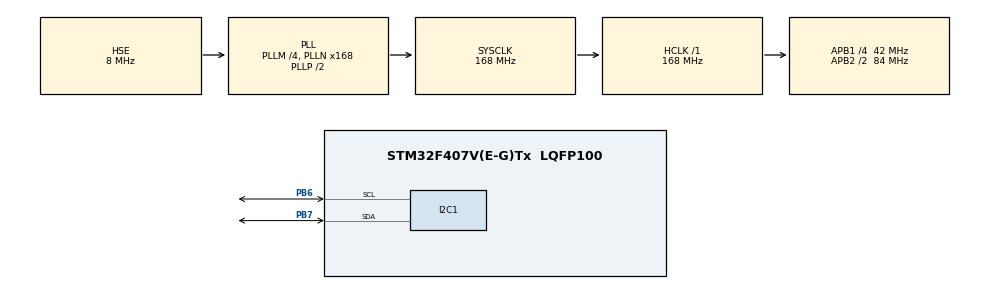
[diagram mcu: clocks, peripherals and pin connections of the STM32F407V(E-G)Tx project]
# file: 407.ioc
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Mcu.Family=STM32F4
Mcu.Name=STM32F407V(E-G)Tx
Mcu.Package=LQFP100
NVIC.PriorityGroup=NVIC_PRIORITYGROUP_4
PA13.Mode=Serial_Wire
PA13.Signal=SYS_JTMS-SWDIO
PA14.Mode=Serial_Wire
PA14.Signal=SYS_JTCK-SWCLK
PB6.Mode=I2C
PB6.Signal=I2C1_SCL
PB7.Mode=I2C
PB7.Signal=I2C1_SDA
PH0-OSC_IN.Mode=HSE-External-Oscillator
PH0-OSC_IN.Signal=RCC_OSC_IN
PH1-OSC_OUT.Mode=HSE-External-Oscillator
PH1-OSC_OUT.Signal=RCC_OSC_OUT
ProjectManager.HeapSize=0x200
ProjectManager.StackSize=0x400
ProjectManager.TargetToolchain=MDK-ARM V5.27
RCC.48MHZClocksFreq_Value=84000000
RCC.AHBFreq_Value=168000000
RCC.APB1CLKDivider=RCC_HCLK_DIV4
RCC.APB1Freq_Value=42000000
RCC.APB1TimFreq_Value=84000000
RCC.APB2CLKDivider=RCC_HCLK_DIV2
RCC.APB2Freq_Value=84000000
RCC.APB2TimFreq_Value=168000000
RCC.CortexFreq_Value=168000000
RCC.HCLKFreq_Value=168000000
RCC.HSE_VALUE=8000000
RCC.HSI_VALUE=16000000
RCC.LSE_VALUE=32768
RCC.PLLM=4
RCC.PLLN=168
RCC.PLLSourceVirtual=RCC_PLLSOURCE_HSE
RCC.SYSCLKFreq_VALUE=168000000
RCC.SYSCLKSource=RCC_SYSCLKSOURCE_PLLCLK
RCC.VCOOutputFreq_Value=336000000
board=custom

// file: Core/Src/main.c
/* USER CODE BEGIN Header */
/***************************************************************************//**
  文件: main.c
  作者: Zhengyu https://gzwelink.taobao.com
  版本: V1.0.0
  时间: 20220401
	平台:MINI-F407VET6

*******************************************************************************/
/* USER CODE END Header */
#include "main.h"
#include "i2c.h"
#include "gpio.h"
#include "oled.h"
/* USER CODE BEGIN Includes */
uint8_t DataBuff[2];//存储数组
float LightData;//光照强度（含小数位，单位lx）
uint32_t LightData_Hex;//光照强度（整数，单位lx）
/* USER CODE END Includes */

/* USER CODE BEGIN PTD */
//写入1字节数据到BH170,设备地址0x46
void BH170_WriteReg(uint8_t reg_add,uint8_t reg_dat)
{
	HAL_I2C_Mem_Write(&hi2c1,0x46,reg_add,1,&reg_dat,1,1000);
}

//读取BH170数据,设备地址0x46
void BH170_ReadData(uint8_t reg_add,unsigned char*Read,uint8_t num)
{
 HAL_I2C_Mem_Read(&hi2c1,0x46,reg_add,1,Read,num,1000);
}
/* USER CODE END PTD */

void SystemClock_Config(void);

int main(void)
{

  /* MCU Configuration--------------------------------------------------------*/

  /* Reset of all peripherals, Initializes the Flash interface and the Systick. */
  HAL_Init();

  /* Configure the system clock */
  SystemClock_Config();

  /* Initialize all configured peripherals */
  MX_GPIO_Init();
  MX_I2C1_Init();
  /* USER CODE BEGIN 2 */
	OLED_Init();//OLED初始化
	OLED_Clear();//OLED清屏

	BH170_WriteReg(0x01,0x00);// power on
	BH170_WriteReg(0x10,0x00);//H- resolution mode
	HAL_Delay(180);
  /* USER CODE END 2 */

  /* Infinite loop */
  while (1)
  {

    /* USER CODE BEGIN 3 */
		BH170_WriteReg(0x01,0x00);// power on
		BH170_WriteReg(0x10,0x00);//H- resolution mode
		HAL_Delay(180);//等待180ms
		BH170_ReadData(0,DataBuff,2);//读取数据
		LightData=((DataBuff[0]<<8)+DataBuff[1])/1.2f;//数据转换成光强度，单位lx
    LightData_Hex=LightData;//float转换成整数
		OLED_ShowNum(6,3,LightData_Hex,5,16);//显示光强度
		OLED_ShowString(72,3,"lx");//显示光强度单位lx
		OLED_ShowCHinese(18,0,0);//光
		OLED_ShowCHinese(36,0,1);//子
		OLED_ShowCHinese(54,0,2);//物
		OLED_ShowCHinese(72,0,3);//联
		OLED_ShowCHinese(90,0,4);//网
  }
  /* USER CODE END 3 */
}

void SystemClock_Config(void)
{
  RCC_OscInitTypeDef RCC_OscInitStruct = {0};
  RCC_ClkInitTypeDef RCC_ClkInitStruct = {0};

  /** Configure the main internal regulator output voltage
  */
  __HAL_RCC_PWR_CLK_ENABLE();
  __HAL_PWR_VOLTAGESCALING_CONFIG(PWR_REGULATOR_VOLTAGE_SCALE1);
  /** Initializes the RCC Oscillators according to the specified parameters
  * in the RCC_OscInitTypeDef structure.
  */
  RCC_OscInitStruct.OscillatorType = RCC_OSCILLATORTYPE_HSE;
  RCC_OscInitStruct.HSEState = RCC_HSE_ON;
  RCC_OscInitStruct.PLL.PLLState = RCC_PLL_ON;
  RCC_OscInitStruct.PLL.PLLSource = RCC_PLLSOURCE_HSE;
  RCC_OscInitStruct.PLL.PLLM = 4;
  RCC_OscInitStruct.PLL.PLLN = 168;
  RCC_OscInitStruct.PLL.PLLP = RCC_PLLP_DIV2;
  RCC_OscInitStruct.PLL.PLLQ = 4;
  if (HAL_RCC_OscConfig(&RCC_OscInitStruct) != HAL_OK)
  {
    Error_Handler();
  }
  /** Initializes the CPU, AHB and APB buses clocks
  */
  RCC_ClkInitStruct.ClockType = RCC_CLOCKTYPE_HCLK|RCC_CLOCKTYPE_SYSCLK
                              |RCC_CLOCKTYPE_PCLK1|RCC_CLOCKTYPE_PCLK2;
  RCC_ClkInitStruct.SYSCLKSource = RCC_SYSCLKSOURCE_PLLCLK;
  RCC_ClkInitStruct.AHBCLKDivider = RCC_SYSCLK_DIV1;
  RCC_ClkInitStruct.APB1CLKDivider = RCC_HCLK_DIV4;
  RCC_ClkInitStruct.APB2CLKDivider = RCC_HCLK_DIV2;

  if (HAL_RCC_ClockConfig(&RCC_ClkInitStruct, FLASH_LATENCY_5) != HAL_OK)
  {
    Error_Handler();
  }
}

void Error_Handler(void)
{
  __disable_irq();
  while (1)
  {
  }
}

/************************ (C) COPYRIGHT STMicroelectronics *****END OF FILE****/
